AUTOSAR XML (schema 3.1.2)
package /Components/SWC_StopStrtEm
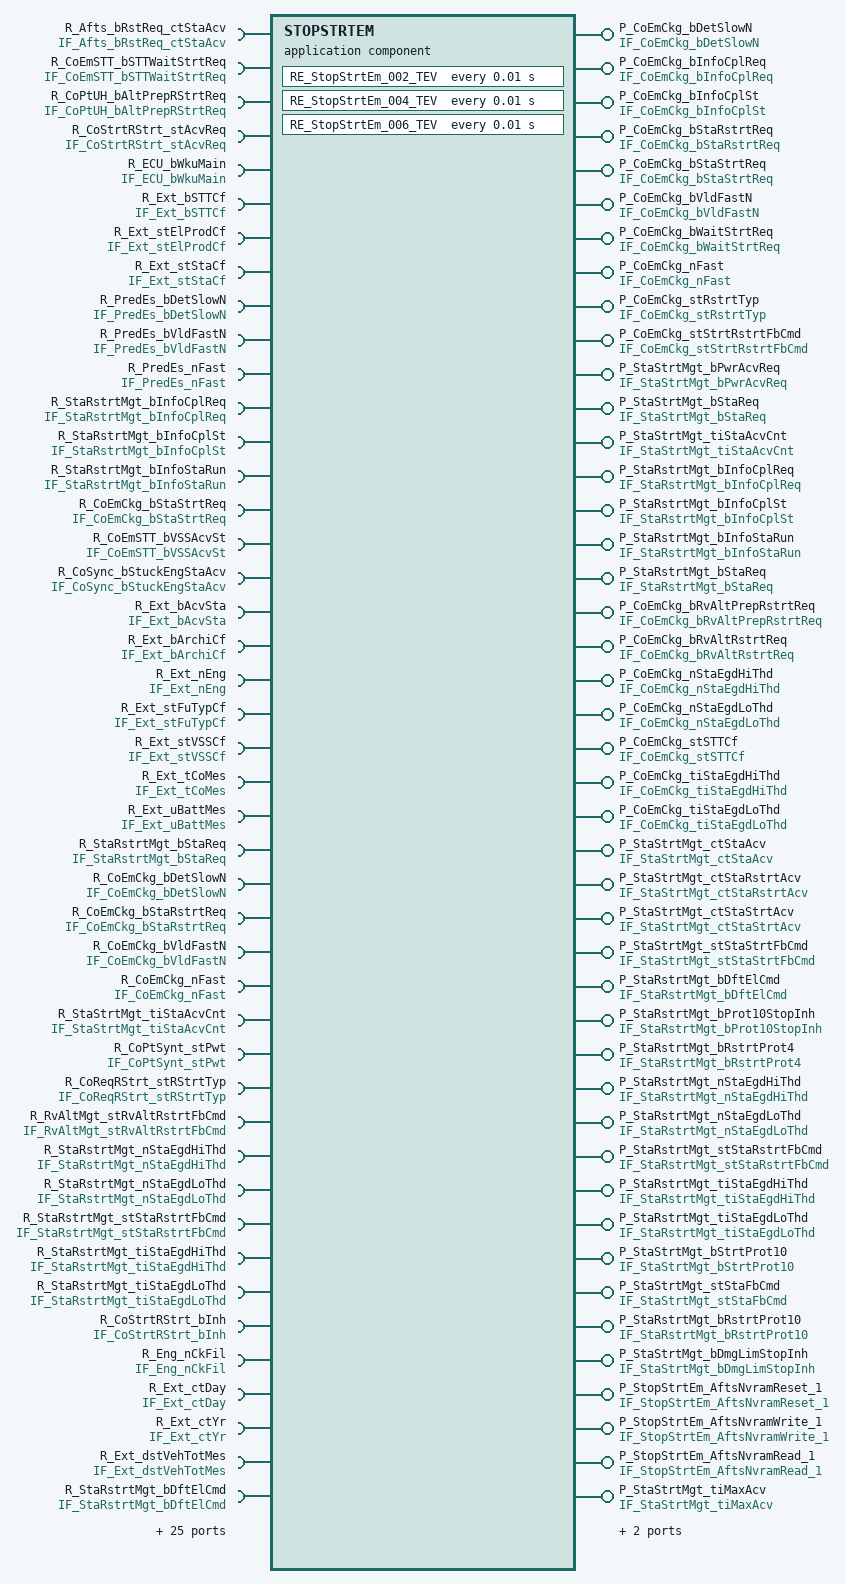
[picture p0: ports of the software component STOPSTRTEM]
  application software component type STOPSTRTEM
    57 x require port:
      R_Afts_bRstReq_ctStaAcv: unqueued-receiver-com-spec{data-element=Afts_bRstReq_ctStaAcv, init-value=Afts_bRstReq_ctStaAcv_in, resync-time=0}, required-interface=IF_Afts_bRstReq_ctStaAcv
      R_CoEmSTT_bSTTWaitStrtReq: unqueued-receiver-com-spec{data-element=CoEmSTT_bSTTWaitStrtReq, init-value=ConstantValue, resync-time=0}, required-interface=IF_CoEmSTT_bSTTWaitStrtReq
      R_CoPtUH_bAltPrepRStrtReq: unqueued-receiver-com-spec{data-element=CoPtUH_bAltPrepRStrtReq, init-value=ConstantValue1, resync-time=0}, required-interface=IF_CoPtUH_bAltPrepRStrtReq
      R_CoStrtRStrt_stAcvReq: unqueued-receiver-com-spec{data-element=CoStrtRStrt_stAcvReq, init-value=ConstantValue3, resync-time=0}, required-interface=IF_CoStrtRStrt_stAcvReq
      R_ECU_bWkuMain: unqueued-receiver-com-spec{data-element=ECU_bWkuMain, init-value=ConstantValue5, resync-time=0}, required-interface=IF_ECU_bWkuMain
      R_Ext_bSTTCf: unqueued-receiver-com-spec{data-element=Ext_bSTTCf, init-value=ConstantValue7, resync-time=0}, required-interface=IF_Ext_bSTTCf
      R_Ext_stElProdCf: unqueued-receiver-com-spec{data-element=Ext_stElProdCf, init-value=ConstantValue9, resync-time=0}, required-interface=IF_Ext_stElProdCf
      R_Ext_stStaCf: unqueued-receiver-com-spec{data-element=Ext_stStaCf, init-value=Ext_stStaCf_in, resync-time=0}, required-interface=IF_Ext_stStaCf
      R_PredEs_bDetSlowN: unqueued-receiver-com-spec{data-element=PredEs_bDetSlowN, init-value=PredEs_bDetSlowN_in, resync-time=0}, required-interface=IF_PredEs_bDetSlowN
      R_PredEs_bVldFastN: unqueued-receiver-com-spec{data-element=PredEs_bVldFastN, init-value=ConstantValue11, resync-time=0}, required-interface=IF_PredEs_bVldFastN
      R_PredEs_nFast: unqueued-receiver-com-spec{data-element=PredEs_nFast, init-value=ConstantValue13, resync-time=0}, required-interface=IF_PredEs_nFast
      R_StaRstrtMgt_bInfoCplReq: unqueued-receiver-com-spec{data-element=StaRstrtMgt_bInfoCplReq, init-value=StaRstrtMgt_bInfoCplReq_in, resync-time=0}, required-interface=IF_StaRstrtMgt_bInfoCplReq
      R_StaRstrtMgt_bInfoCplSt: unqueued-receiver-com-spec{data-element=StaRstrtMgt_bInfoCplSt, init-value=StaRstrtMgt_bInfoCplSt_in, resync-time=0}, required-interface=IF_StaRstrtMgt_bInfoCplSt
      R_StaRstrtMgt_bInfoStaRun: unqueued-receiver-com-spec{data-element=StaRstrtMgt_bInfoStaRun, init-value=StaRstrtMgt_bInfoStaRun_in, resync-time=0}, required-interface=IF_StaRstrtMgt_bInfoStaRun
      R_CoEmCkg_bStaStrtReq: unqueued-receiver-com-spec{data-element=CoEmCkg_bStaStrtReq, init-value=CoEmCkg_bStaStrtReq_in, resync-time=0}, required-interface=IF_CoEmCkg_bStaStrtReq
      R_CoEmSTT_bVSSAcvSt: unqueued-receiver-com-spec{data-element=CoEmSTT_bVSSAcvSt, init-value=ConstantValue15, resync-time=0}, required-interface=IF_CoEmSTT_bVSSAcvSt
      R_CoSync_bStuckEngStaAcv: unqueued-receiver-com-spec{data-element=CoSync_bStuckEngStaAcv, init-value=ConstantValue17, resync-time=0}, required-interface=IF_CoSync_bStuckEngStaAcv
      R_Ext_bAcvSta: unqueued-receiver-com-spec{data-element=Ext_bAcvSta, init-value=Ext_bAcvSta_in, resync-time=0}, required-interface=IF_Ext_bAcvSta
      R_Ext_bArchiCf: unqueued-receiver-com-spec{data-element=Ext_bArchiCf, init-value=ConstantValue19, resync-time=0}, required-interface=IF_Ext_bArchiCf
      R_Ext_nEng: unqueued-receiver-com-spec{data-element=Ext_nEng, init-value=ConstantValue21, resync-time=0}, required-interface=IF_Ext_nEng
      R_Ext_stFuTypCf: unqueued-receiver-com-spec{data-element=Ext_stFuTypCf, init-value=Ext_stFuTypCf_in, resync-time=0}, required-interface=IF_Ext_stFuTypCf
      R_Ext_stVSSCf: unqueued-receiver-com-spec{data-element=Ext_stVSSCf, init-value=ConstantValue23, resync-time=0}, required-interface=IF_Ext_stVSSCf
      R_Ext_tCoMes: unqueued-receiver-com-spec{data-element=Ext_tCoMes, init-value=ConstantValue25, resync-time=0}, required-interface=IF_Ext_tCoMes
      R_Ext_uBattMes: unqueued-receiver-com-spec{data-element=Ext_uBattMes, init-value=ConstantValue27, resync-time=0}, required-interface=IF_Ext_uBattMes
      R_StaRstrtMgt_bStaReq: unqueued-receiver-com-spec{data-element=StaRstrtMgt_bStaReq, init-value=StaRstrtMgt_bStaReq_in, resync-time=0}, required-interface=IF_StaRstrtMgt_bStaReq
      R_CoEmCkg_bDetSlowN: unqueued-receiver-com-spec{data-element=CoEmCkg_bDetSlowN, init-value=CoEmCkg_bDetSlowN_in, resync-time=0}, required-interface=IF_CoEmCkg_bDetSlowN
      R_CoEmCkg_bStaRstrtReq: unqueued-receiver-com-spec{data-element=CoEmCkg_bStaRstrtReq, init-value=CoEmCkg_bStaRstrtReq_in, resync-time=0}, required-interface=IF_CoEmCkg_bStaRstrtReq
      R_CoEmCkg_bVldFastN: unqueued-receiver-com-spec{data-element=CoEmCkg_bVldFastN, init-value=CoEmCkg_bVldFastN_in, resync-time=0}, required-interface=IF_CoEmCkg_bVldFastN
      R_CoEmCkg_nFast: unqueued-receiver-com-spec{data-element=CoEmCkg_nFast, init-value=CoEmCkg_nFast_in, resync-time=0}, required-interface=IF_CoEmCkg_nFast
      R_StaStrtMgt_tiStaAcvCnt: unqueued-receiver-com-spec{data-element=StaStrtMgt_tiStaAcvCnt, init-value=StaStrtMgt_tiStaAcvCnt_in, resync-time=0}, required-interface=IF_StaStrtMgt_tiStaAcvCnt
      R_CoPtSynt_stPwt: unqueued-receiver-com-spec{data-element=CoPtSynt_stPwt, init-value=ConstantValue29, resync-time=0}, required-interface=IF_CoPtSynt_stPwt
      R_CoReqRStrt_stRStrtTyp: unqueued-receiver-com-spec{data-element=CoReqRStrt_stRStrtTyp, init-value=ConstantValue31, resync-time=0}, required-interface=IF_CoReqRStrt_stRStrtTyp
      R_RvAltMgt_stRvAltRstrtFbCmd: unqueued-receiver-com-spec{data-element=RvAltMgt_stRvAltRstrtFbCmd, init-value=ConstantValue33, resync-time=0}, required-interface=IF_RvAltMgt_stRvAltRstrtFbCmd
      R_StaRstrtMgt_nStaEgdHiThd: unqueued-receiver-com-spec{data-element=StaRstrtMgt_nStaEgdHiThd, init-value=StaRstrtMgt_nStaEgdHiThd_in, resync-time=0}, required-interface=IF_StaRstrtMgt_nStaEgdHiThd
      R_StaRstrtMgt_nStaEgdLoThd: unqueued-receiver-com-spec{data-element=StaRstrtMgt_nStaEgdLoThd, init-value=StaRstrtMgt_nStaEgdLoThd_in, resync-time=0}, required-interface=IF_StaRstrtMgt_nStaEgdLoThd
      R_StaRstrtMgt_stStaRstrtFbCmd: unqueued-receiver-com-spec{data-element=StaRstrtMgt_stStaRstrtFbCmd, init-value=ConstantValue35, resync-time=0}, required-interface=IF_StaRstrtMgt_stStaRstrtFbCmd
      R_StaRstrtMgt_tiStaEgdHiThd: unqueued-receiver-com-spec{data-element=StaRstrtMgt_tiStaEgdHiThd, init-value=StaRstrtMgt_tiStaEgdHiThd_in, resync-time=0}, required-interface=IF_StaRstrtMgt_tiStaEgdHiThd
      R_StaRstrtMgt_tiStaEgdLoThd: unqueued-receiver-com-spec{data-element=StaRstrtMgt_tiStaEgdLoThd, init-value=StaRstrtMgt_tiStaEgdLoThd_in, resync-time=0}, required-interface=IF_StaRstrtMgt_tiStaEgdLoThd
      R_CoStrtRStrt_bInh: unqueued-receiver-com-spec{data-element=CoStrtRStrt_bInh, init-value=CoStrtRStrt_bInh_in, resync-time=0}, required-interface=IF_CoStrtRStrt_bInh
      R_Eng_nCkFil: unqueued-receiver-com-spec{data-element=Eng_nCkFil, init-value=ConstantValue37, resync-time=0}, required-interface=IF_Eng_nCkFil
      R_Ext_ctDay: unqueued-receiver-com-spec{data-element=Ext_ctDay, init-value=ConstantValue39, resync-time=0}, required-interface=IF_Ext_ctDay
      R_Ext_ctYr: unqueued-receiver-com-spec{data-element=Ext_ctYr, init-value=ConstantValue41, resync-time=0}, required-interface=IF_Ext_ctYr
      R_Ext_dstVehTotMes: unqueued-receiver-com-spec{data-element=Ext_dstVehTotMes, init-value=ConstantValue43, resync-time=0}, required-interface=IF_Ext_dstVehTotMes
      R_StaRstrtMgt_bDftElCmd: unqueued-receiver-com-spec{data-element=StaRstrtMgt_bDftElCmd, init-value=StaRstrtMgt_bDftElCmd_in, resync-time=0}, required-interface=IF_StaRstrtMgt_bDftElCmd
      R_StaRstrtMgt_bRstrtProt4: unqueued-receiver-com-spec{data-element=StaRstrtMgt_bRstrtProt4, init-value=StaRstrtMgt_bRstrtProt4_in, resync-time=0}, required-interface=IF_StaRstrtMgt_bRstrtProt4
      R_StaStrtMgt_ctStaAcv: unqueued-receiver-com-spec{data-element=StaStrtMgt_ctStaAcv, init-value=StaStrtMgt_ctStaAcv_in, resync-time=0}, required-interface=IF_StaStrtMgt_ctStaAcv
      R_StaStrtMgt_stStaFbCmd: unqueued-receiver-com-spec{data-element=StaStrtMgt_stStaFbCmd, init-value=StaStrtMgt_stStaFbCmd_in, resync-time=0}, required-interface=IF_StaStrtMgt_stStaFbCmd
      R_CoEmCkg_stSTTCf: unqueued-receiver-com-spec{data-element=CoEmCkg_stSTTCf, init-value=ConstantValue45, resync-time=0}, required-interface=IF_CoEmCkg_stSTTCf
      R_Ext_bStaCmdFctSt: unqueued-receiver-com-spec{data-element=Ext_bStaCmdFctSt, init-value=Ext_bStaCmdFctSt_in, resync-time=0}, required-interface=IF_Ext_bStaCmdFctSt
      R_FRM_bAcvStaStrtMgtDftValThd: required-interface=FunctionInhibition
      R_FRM_bAcvStaStrtMgtDiagElCmd: required-interface=FunctionInhibition
      R_FRM_bInhStaStrtMgtVoltFall: required-interface=FunctionInhibition
      R_FRM_bAcvStaRstrtMgtDftValThd: required-interface=FunctionInhibition
      R_FRM_bAcvStaRstrtMgtDiagElCmd: required-interface=FunctionInhibition
      R_FRM_bInhStaRstrtMgtVoltFall: required-interface=FunctionInhibition
      R_FRM_bInhStaStrtMgtDmgTiCnt: required-interface=FunctionInhibition
      R_FRM_bInhStaStrtMgtDmgVehDst: required-interface=FunctionInhibition
    40 x provide port:
      P_CoEmCkg_bDetSlowN: unqueued-sender-com-spec{data-element=CoEmCkg_bDetSlowN, can-invalidate=false, init-value=CoEmCkg_bDetSlowN_out}, provided-interface=IF_CoEmCkg_bDetSlowN
      P_CoEmCkg_bInfoCplReq: unqueued-sender-com-spec{data-element=CoEmCkg_bInfoCplReq, can-invalidate=false, init-value=CoEmCkg_bInfoCplReq_out}, provided-interface=IF_CoEmCkg_bInfoCplReq
      P_CoEmCkg_bInfoCplSt: unqueued-sender-com-spec{data-element=CoEmCkg_bInfoCplSt, can-invalidate=false, init-value=CoEmCkg_bInfoCplSt_out}, provided-interface=IF_CoEmCkg_bInfoCplSt
      P_CoEmCkg_bStaRstrtReq: unqueued-sender-com-spec{data-element=CoEmCkg_bStaRstrtReq, can-invalidate=false, init-value=CoEmCkg_bStaRstrtReq_out}, provided-interface=IF_CoEmCkg_bStaRstrtReq
      P_CoEmCkg_bStaStrtReq: unqueued-sender-com-spec{data-element=CoEmCkg_bStaStrtReq, can-invalidate=false, init-value=CoEmCkg_bStaStrtReq_out}, provided-interface=IF_CoEmCkg_bStaStrtReq
      P_CoEmCkg_bVldFastN: unqueued-sender-com-spec{data-element=CoEmCkg_bVldFastN, can-invalidate=false, init-value=CoEmCkg_bVldFastN_out}, provided-interface=IF_CoEmCkg_bVldFastN
      P_CoEmCkg_bWaitStrtReq: unqueued-sender-com-spec{data-element=CoEmCkg_bWaitStrtReq, can-invalidate=false, init-value=CoEmCkg_bWaitStrtReq_out}, provided-interface=IF_CoEmCkg_bWaitStrtReq
      P_CoEmCkg_nFast: unqueued-sender-com-spec{data-element=CoEmCkg_nFast, can-invalidate=false, init-value=CoEmCkg_nFast_out}, provided-interface=IF_CoEmCkg_nFast
      P_CoEmCkg_stRstrtTyp: unqueued-sender-com-spec{data-element=CoEmCkg_stRstrtTyp, can-invalidate=false, init-value=ConstantValue47}, provided-interface=IF_CoEmCkg_stRstrtTyp
      P_CoEmCkg_stStrtRstrtFbCmd: unqueued-sender-com-spec{data-element=CoEmCkg_stStrtRstrtFbCmd, can-invalidate=false, init-value=ConstantValue49}, provided-interface=IF_CoEmCkg_stStrtRstrtFbCmd
      P_StaStrtMgt_bPwrAcvReq: unqueued-sender-com-spec{data-element=StaStrtMgt_bPwrAcvReq, can-invalidate=false, init-value=StaStrtMgt_bPwrAcvReq_out}, provided-interface=IF_StaStrtMgt_bPwrAcvReq
      P_StaStrtMgt_bStaReq: unqueued-sender-com-spec{data-element=StaStrtMgt_bStaReq, can-invalidate=false, init-value=ConstantValue51}, provided-interface=IF_StaStrtMgt_bStaReq
      P_StaStrtMgt_tiStaAcvCnt: unqueued-sender-com-spec{data-element=StaStrtMgt_tiStaAcvCnt, can-invalidate=false, init-value=StaStrtMgt_tiStaAcvCnt_out}, provided-interface=IF_StaStrtMgt_tiStaAcvCnt
      P_StaRstrtMgt_bInfoCplReq: unqueued-sender-com-spec{data-element=StaRstrtMgt_bInfoCplReq, can-invalidate=false, init-value=StaRstrtMgt_bInfoCplReq_out}, provided-interface=IF_StaRstrtMgt_bInfoCplReq
      P_StaRstrtMgt_bInfoCplSt: unqueued-sender-com-spec{data-element=StaRstrtMgt_bInfoCplSt, can-invalidate=false, init-value=StaRstrtMgt_bInfoCplSt_out}, provided-interface=IF_StaRstrtMgt_bInfoCplSt
      P_StaRstrtMgt_bInfoStaRun: unqueued-sender-com-spec{data-element=StaRstrtMgt_bInfoStaRun, can-invalidate=false, init-value=StaRstrtMgt_bInfoStaRun_out}, provided-interface=IF_StaRstrtMgt_bInfoStaRun
      P_StaRstrtMgt_bStaReq: unqueued-sender-com-spec{data-element=StaRstrtMgt_bStaReq, can-invalidate=false, init-value=StaRstrtMgt_bStaReq_out}, provided-interface=IF_StaRstrtMgt_bStaReq
      P_CoEmCkg_bRvAltPrepRstrtReq: unqueued-sender-com-spec{data-element=CoEmCkg_bRvAltPrepRstrtReq, can-invalidate=false, init-value=CoEmCkg_bRvAltPrepRstrtReq_out}, provided-interface=IF_CoEmCkg_bRvAltPrepRstrtReq
      P_CoEmCkg_bRvAltRstrtReq: unqueued-sender-com-spec{data-element=CoEmCkg_bRvAltRstrtReq, can-invalidate=false, init-value=CoEmCkg_bRvAltRstrtReq_out}, provided-interface=IF_CoEmCkg_bRvAltRstrtReq
      P_CoEmCkg_nStaEgdHiThd: unqueued-sender-com-spec{data-element=CoEmCkg_nStaEgdHiThd, can-invalidate=false, init-value=CoEmCkg_nStaEgdHiThd_out}, provided-interface=IF_CoEmCkg_nStaEgdHiThd
      P_CoEmCkg_nStaEgdLoThd: unqueued-sender-com-spec{data-element=CoEmCkg_nStaEgdLoThd, can-invalidate=false, init-value=CoEmCkg_nStaEgdLoThd_out}, provided-interface=IF_CoEmCkg_nStaEgdLoThd
      P_CoEmCkg_stSTTCf: unqueued-sender-com-spec{data-element=CoEmCkg_stSTTCf, can-invalidate=false, init-value=ConstantValue53}, provided-interface=IF_CoEmCkg_stSTTCf
      P_CoEmCkg_tiStaEgdHiThd: unqueued-sender-com-spec{data-element=CoEmCkg_tiStaEgdHiThd, can-invalidate=false, init-value=CoEmCkg_tiStaEgdHiThd_out}, provided-interface=IF_CoEmCkg_tiStaEgdHiThd
      P_CoEmCkg_tiStaEgdLoThd: unqueued-sender-com-spec{data-element=CoEmCkg_tiStaEgdLoThd, can-invalidate=false, init-value=CoEmCkg_tiStaEgdLoThd_out}, provided-interface=IF_CoEmCkg_tiStaEgdLoThd
      P_StaStrtMgt_ctStaAcv: unqueued-sender-com-spec{data-element=StaStrtMgt_ctStaAcv, can-invalidate=false, init-value=StaStrtMgt_ctStaAcv_out}, provided-interface=IF_StaStrtMgt_ctStaAcv
      P_StaStrtMgt_ctStaRstrtAcv: unqueued-sender-com-spec{data-element=StaStrtMgt_ctStaRstrtAcv, can-invalidate=false, init-value=StaStrtMgt_ctStaRstrtAcv_out}, provided-interface=IF_StaStrtMgt_ctStaRstrtAcv
      P_StaStrtMgt_ctStaStrtAcv: unqueued-sender-com-spec{data-element=StaStrtMgt_ctStaStrtAcv, can-invalidate=false, init-value=StaStrtMgt_ctStaStrtAcv_out}, provided-interface=IF_StaStrtMgt_ctStaStrtAcv
      P_StaStrtMgt_stStaStrtFbCmd: unqueued-sender-com-spec{data-element=StaStrtMgt_stStaStrtFbCmd, can-invalidate=false, init-value=StaStrtMgt_stStaStrtFbCmd_out}, provided-interface=IF_StaStrtMgt_stStaStrtFbCmd
      P_StaRstrtMgt_bDftElCmd: unqueued-sender-com-spec{data-element=StaRstrtMgt_bDftElCmd, can-invalidate=false, init-value=StaRstrtMgt_bDftElCmd_out}, provided-interface=IF_StaRstrtMgt_bDftElCmd
      P_StaRstrtMgt_bProt10StopInh: unqueued-sender-com-spec{data-element=StaRstrtMgt_bProt10StopInh, can-invalidate=false, init-value=ConstantValue55}, provided-interface=IF_StaRstrtMgt_bProt10StopInh
      P_StaRstrtMgt_bRstrtProt4: unqueued-sender-com-spec{data-element=StaRstrtMgt_bRstrtProt4, can-invalidate=false, init-value=StaRstrtMgt_bRstrtProt4_out}, provided-interface=IF_StaRstrtMgt_bRstrtProt4
      P_StaRstrtMgt_nStaEgdHiThd: unqueued-sender-com-spec{data-element=StaRstrtMgt_nStaEgdHiThd, can-invalidate=false, init-value=StaRstrtMgt_nStaEgdHiThd_out}, provided-interface=IF_StaRstrtMgt_nStaEgdHiThd
      P_StaRstrtMgt_nStaEgdLoThd: unqueued-sender-com-spec{data-element=StaRstrtMgt_nStaEgdLoThd, can-invalidate=false, init-value=StaRstrtMgt_nStaEgdLoThd_out}, provided-interface=IF_StaRstrtMgt_nStaEgdLoThd
      P_StaRstrtMgt_stStaRstrtFbCmd: unqueued-sender-com-spec{data-element=StaRstrtMgt_stStaRstrtFbCmd, can-invalidate=false, init-value=ConstantValue57}, provided-interface=IF_StaRstrtMgt_stStaRstrtFbCmd
      P_StaRstrtMgt_tiStaEgdHiThd: unqueued-sender-com-spec{data-element=StaRstrtMgt_tiStaEgdHiThd, can-invalidate=false, init-value=StaRstrtMgt_tiStaEgdHiThd_out}, provided-interface=IF_StaRstrtMgt_tiStaEgdHiThd
      P_StaRstrtMgt_tiStaEgdLoThd: unqueued-sender-com-spec{data-element=StaRstrtMgt_tiStaEgdLoThd, can-invalidate=false, init-value=StaRstrtMgt_tiStaEgdLoThd_out}, provided-interface=IF_StaRstrtMgt_tiStaEgdLoThd
      P_StaStrtMgt_bStrtProt10: unqueued-sender-com-spec{data-element=StaStrtMgt_bStrtProt10, can-invalidate=false, init-value=StaStrtMgt_bStrtProt10_out}, provided-interface=IF_StaStrtMgt_bStrtProt10
      P_StaStrtMgt_stStaFbCmd: unqueued-sender-com-spec{data-element=StaStrtMgt_stStaFbCmd, can-invalidate=false, init-value=StaStrtMgt_stStaFbCmd_out}, provided-interface=IF_StaStrtMgt_stStaFbCmd
      P_StaRstrtMgt_bRstrtProt10: unqueued-sender-com-spec{data-element=StaRstrtMgt_bRstrtProt10, can-invalidate=false, init-value=StaRstrtMgt_bRstrtProt10_out}, provided-interface=IF_StaRstrtMgt_bRstrtProt10
      P_StaStrtMgt_bDmgLimStopInh: unqueued-sender-com-spec{data-element=StaStrtMgt_bDmgLimStopInh, can-invalidate=false, init-value=ConstantValue59}, provided-interface=IF_StaStrtMgt_bDmgLimStopInh
    8 x require port:
      R_StaStrtMgt_StaCmd: required-interface=DiagnosticMonitor
      R_StaStrtMgt_StaElCmd: required-interface=DiagnosticMonitor
      R_StaStrtMgt_StuckMec: required-interface=DiagnosticMonitor
      R_StaStrtMgt_StaAcvThd1: required-interface=DiagnosticMonitor
      R_StaStrtMgt_StaAcvThd2: required-interface=DiagnosticMonitor
      R_StaStrtMgt_StaCmdInfo: required-interface=DiagnosticMonitor
      R_UCE_stWkuMainRelSt: required-interface=IF_UCE_stWkuMainRelSt
      R_EcuM_CurrentMode: required-interface=EcuM_CurrentMode
    provide port P_StopStrtEm_AftsNvramReset_1: server-com-spec{operation=op_StopStrtEm_AftsNvramReset_1, queue-length=1}, provided-interface=IF_StopStrtEm_AftsNvramReset_1
    provide port P_StopStrtEm_AftsNvramWrite_1: server-com-spec{operation=op_StopStrtEm_AftsNvramWrite_1, queue-length=1}, provided-interface=IF_StopStrtEm_AftsNvramWrite_1
    provide port P_StopStrtEm_AftsNvramRead_1: server-com-spec{operation=op_StopStrtEm_AftsNvramRead_1, queue-length=1}, provided-interface=IF_StopStrtEm_AftsNvramRead_1
    require port R_Ext_ctSec: unqueued-receiver-com-spec{data-element=Ext_ctSec, init-value=ConstantValue61, resync-time=0}, required-interface=IF_Ext_ctSec
    provide port P_StaStrtMgt_tiMaxAcv: unqueued-sender-com-spec{data-element=StaStrtMgt_tiMaxAcv, can-invalidate=false, init-value=StaStrtMgt_tiMaxAcv_Cst}, provided-interface=IF_StaStrtMgt_tiMaxAcv
    require port R_StaStrtMgt_tiMaxAcv: unqueued-receiver-com-spec{data-element=StaStrtMgt_tiMaxAcv, init-value=StaStrtMgt_tiMaxAcv_Cst, resync-time=0}, required-interface=IF_StaStrtMgt_tiMaxAcv
    provide port P_CoEmCkg_bReqAltBoostFil: unqueued-sender-com-spec{data-element=CoEmCkg_bReqAltBoostFil, can-invalidate=false, init-value=CoEmCkg_bReqAltBoostFil_Cst}, provided-interface=IF_CoEmCkg_bReqAltBoostFil
    provide port P_CoEmCkg_stReqAltBoost: unqueued-sender-com-spec{data-element=CoEmCkg_stReqAltBoost, can-invalidate=false, init-value=CoEmCkg_stReqAltBoost_Cst}, provided-interface=IF_CoEmCkg_stReqAltBoost
    require port R_CoEmSTT_bAuthBoost: unqueued-receiver-com-spec{data-element=CoEmSTT_bAuthBoost, init-value=CoEmSTT_bAuthBoost_Cst, resync-time=0}, required-interface=IF_CoEmSTT_bAuthBoost
    require port R_TqLimUH_bAcvUnBlsEng: unqueued-receiver-com-spec{data-element=TqLimUH_bAcvUnBlsEng, init-value=ConstantValue63, resync-time=0}, required-interface=IF_TqLimUH_bAcvUnBlsEng
  95 x constant specification:
    Afts_bRstReq_ctStaAcv_in
      value:
        boolean literal Afts_bRstReq_ctStaAcv_in: type=DT_Afts_bRstReq_ctStaAcv, value=false
    CoEmCkg_bDetSlowN_in
      value:
        boolean literal CoEmCkg_bDetSlowN_in: type=DT_CoEmCkg_bDetSlowN, value=false
    CoEmCkg_bDetSlowN_out
      value:
        boolean literal CoEmCkg_bDetSlowN_out: type=DT_CoEmCkg_bDetSlowN, value=false
    CoEmCkg_bInfoCplReq_out
      value:
        boolean literal CoEmCkg_bInfoCplReq_out: type=DT_CoEmCkg_bInfoCplReq, value=false
    CoEmCkg_bInfoCplSt_out
      value:
        boolean literal CoEmCkg_bInfoCplSt_out: type=DT_CoEmCkg_bInfoCplSt, value=false
    CoEmCkg_bReqAltBoostFil_Cst
      value:
        boolean literal CoEmCkg_bReqAltBoostFil_Cst: type=DT_CoEmCkg_bReqAltBoostFil, value=false
    CoEmCkg_bRvAltPrepRstrtReq_out
      value:
        boolean literal CoEmCkg_bRvAltPrepRstrtReq_out: type=DT_CoEmCkg_bRvAltPrepRstrtReq, value=false
    CoEmCkg_bRvAltRstrtReq_out
      value:
        boolean literal CoEmCkg_bRvAltRstrtReq_out: type=DT_CoEmCkg_bRvAltRstrtReq, value=false
    CoEmCkg_bStaRstrtReq_in
      value:
        boolean literal CoEmCkg_bStaRstrtReq_in: type=DT_CoEmCkg_bStaRstrtReq, value=false
    CoEmCkg_bStaRstrtReq_out
      value:
        boolean literal CoEmCkg_bStaRstrtReq_out: type=DT_CoEmCkg_bStaRstrtReq, value=false
    CoEmCkg_bStaStrtReq_in
      value:
        boolean literal CoEmCkg_bStaStrtReq_in: type=DT_CoEmCkg_bStaStrtReq, value=false
    CoEmCkg_bStaStrtReq_out
      value:
        boolean literal CoEmCkg_bStaStrtReq_out: type=DT_CoEmCkg_bStaStrtReq, value=false
    CoEmCkg_bVldFastN_in
      value:
        boolean literal CoEmCkg_bVldFastN_in: type=DT_CoEmCkg_bVldFastN, value=false
    CoEmCkg_bVldFastN_out
      value:
        boolean literal CoEmCkg_bVldFastN_out: type=DT_CoEmCkg_bVldFastN, value=false
    CoEmCkg_bWaitStrtReq_out
      value:
        boolean literal CoEmCkg_bWaitStrtReq_out: type=DT_CoEmCkg_bWaitStrtReq, value=false
    CoEmCkg_nFast_in
      value:
        integer literal CoEmCkg_nFast_in: type=DT_CoEmCkg_nFast, value=0
    CoEmCkg_nFast_out
      value:
        integer literal CoEmCkg_nFast_out: type=DT_CoEmCkg_nFast, value=0
    CoEmCkg_nStaEgdHiThd_out
      value:
        integer literal CoEmCkg_nStaEgdHiThd_out: type=DT_CoEmCkg_nStaEgdHiThd, value=0
    CoEmCkg_nStaEgdLoThd_out
      value:
        integer literal CoEmCkg_nStaEgdLoThd_out: type=DT_CoEmCkg_nStaEgdLoThd, value=0
    CoEmCkg_stReqAltBoost_Cst
      value:
        integer literal CoEmCkg_stReqAltBoost_Cst: type=DT_CoEmCkg_stReqAltBoost, value=0
    CoEmCkg_tiStaEgdHiThd_out
      value:
        integer literal CoEmCkg_tiStaEgdHiThd_out: type=DT_CoEmCkg_tiStaEgdHiThd, value=60
    CoEmCkg_tiStaEgdLoThd_out
      value:
        integer literal CoEmCkg_tiStaEgdLoThd_out: type=DT_CoEmCkg_tiStaEgdLoThd, value=30
    CoEmSTT_bAuthBoost_Cst
      value:
        boolean literal CoEmSTT_bAuthBoost_Cst: type=DT_CoEmSTT_bAuthBoost, value=false
    ConstantValue
      value:
        boolean literal ConstantValue: type=DT_CoEmSTT_bSTTWaitStrtReq, value=false
    ConstantValue1
      value:
        boolean literal ConstantValue1: type=DT_CoPtUH_bAltPrepRStrtReq, value=false
    ConstantValue11
      value:
        boolean literal ConstantValue11: type=DT_PredEs_bVldFastN, value=false
    ConstantValue13
      value:
        integer literal ConstantValue13: type=DT_PredEs_nFast, value=0
    ConstantValue15
      value:
        boolean literal ConstantValue15: type=DT_CoEmSTT_bVSSAcvSt, value=false
    ConstantValue17
      value:
        boolean literal ConstantValue17: type=DT_CoSync_bStuckEngStaAcv, value=false
    ConstantValue19
      value:
        boolean literal ConstantValue19: type=DT_Ext_bArchiCf, value=false
    ConstantValue21
      value:
        integer literal ConstantValue21: type=DT_Ext_nEng, value=0
    ConstantValue23
      value:
        integer literal ConstantValue23: type=DT_Ext_stVSSCf, value=0
    ConstantValue25
      value:
        integer literal ConstantValue25: type=DT_Ext_tCoMes, value=20
    ConstantValue27
      value:
        integer literal ConstantValue27: type=DT_Ext_uBattMes, value=1200
    ConstantValue29
      value:
        integer literal ConstantValue29: type=DT_CoPtSynt_stPwt, value=1
    ConstantValue3
      value:
        integer literal ConstantValue3: type=DT_CoStrtRStrt_stAcvReq, value=0
    ConstantValue31
      value:
        integer literal ConstantValue31: type=DT_CoReqRStrt_stRStrtTyp, value=0
    ConstantValue33
      value:
        integer literal ConstantValue33: type=DT_RvAltMgt_stRvAltRstrtFbCmd, value=0
    ConstantValue35
      value:
        integer literal ConstantValue35: type=DT_StaRstrtMgt_stStaRstrtFbCmd, value=0
    ConstantValue37
      value:
        integer literal ConstantValue37: type=DT_Eng_nCkFil, value=0
    ConstantValue39
      value:
        integer literal ConstantValue39: type=DT_Ext_ctDay, value=0
    ConstantValue41
      value:
        integer literal ConstantValue41: type=DT_Ext_ctYr, value=0
    ConstantValue43
      value:
        integer literal ConstantValue43: type=DT_Ext_dstVehTotMes, value=0
    ConstantValue45
      value:
        integer literal ConstantValue45: type=DT_CoEmCkg_stSTTCf, value=0
    ConstantValue47
      value:
        integer literal ConstantValue47: type=DT_CoEmCkg_stRstrtTyp, value=0
    ConstantValue49
      value:
        integer literal ConstantValue49: type=DT_CoEmCkg_stStrtRstrtFbCmd, value=0
    ConstantValue5
      value:
        boolean literal ConstantValue5: type=DT_ECU_bWkuMain, value=false
    ConstantValue51
      value:
        boolean literal ConstantValue51: type=DT_StaStrtMgt_bStaReq, value=false
    ConstantValue53
      value:
        integer literal ConstantValue53: type=DT_CoEmCkg_stSTTCf, value=0
    ConstantValue55
      value:
        boolean literal ConstantValue55: type=DT_StaRstrtMgt_bProt10StopInh, value=false
    ConstantValue57
      value:
        integer literal ConstantValue57: type=DT_StaRstrtMgt_stStaRstrtFbCmd, value=0
    ConstantValue59
      value:
        boolean literal ConstantValue59: type=DT_StaStrtMgt_bDmgLimStopInh, value=false
    ConstantValue61
      value:
        integer literal ConstantValue61: type=DT_Ext_ctSec, value=0
    ConstantValue63
      value:
        boolean literal ConstantValue63: type=DT_TqLimUH_bAcvUnBlsEng, value=false
    ConstantValue7
      value:
        boolean literal ConstantValue7: type=DT_Ext_bSTTCf, value=false
    ConstantValue9
      value:
        integer literal ConstantValue9: type=DT_Ext_stElProdCf, value=0
    CoStrtRStrt_bInh_in
      value:
        boolean literal CoStrtRStrt_bInh_in: type=DT_CoStrtRStrt_bInh, value=true
    Ext_bAcvSta_in
      value:
        boolean literal Ext_bAcvSta_in: type=DT_Ext_bAcvSta, value=false
    Ext_bStaCmdFctSt_in
      value:
        boolean literal Ext_bStaCmdFctSt_in: type=DT_Ext_bStaCmdFctSt, value=false
    Ext_stFuTypCf_in
      value:
        integer literal Ext_stFuTypCf_in: type=DT_Ext_stFuTypCf, value=0
    Ext_stStaCf_in
      value:
        integer literal Ext_stStaCf_in: type=DT_Ext_stStaCf, value=1
    PredEs_bDetSlowN_in
      value:
        boolean literal PredEs_bDetSlowN_in: type=DT_PredEs_bDetSlowN, value=false
    StaRstrtMgt_bDftElCmd_in
      value:
        boolean literal StaRstrtMgt_bDftElCmd_in: type=DT_StaRstrtMgt_bDftElCmd, value=false
    StaRstrtMgt_bDftElCmd_out
      value:
        boolean literal StaRstrtMgt_bDftElCmd_out: type=DT_StaRstrtMgt_bDftElCmd, value=false
    StaRstrtMgt_bInfoCplReq_in
      value:
        boolean literal StaRstrtMgt_bInfoCplReq_in: type=DT_StaRstrtMgt_bInfoCplReq, value=false
    StaRstrtMgt_bInfoCplReq_out
      value:
        boolean literal StaRstrtMgt_bInfoCplReq_out: type=DT_StaRstrtMgt_bInfoCplReq, value=false
    StaRstrtMgt_bInfoCplSt_in
      value:
        boolean literal StaRstrtMgt_bInfoCplSt_in: type=DT_StaRstrtMgt_bInfoCplSt, value=false
    StaRstrtMgt_bInfoCplSt_out
      value:
        boolean literal StaRstrtMgt_bInfoCplSt_out: type=DT_StaRstrtMgt_bInfoCplSt, value=false
    StaRstrtMgt_bInfoStaRun_in
      value:
        boolean literal StaRstrtMgt_bInfoStaRun_in: type=DT_StaRstrtMgt_bInfoStaRun, value=false
    StaRstrtMgt_bInfoStaRun_out
      value:
        boolean literal StaRstrtMgt_bInfoStaRun_out: type=DT_StaRstrtMgt_bInfoStaRun, value=false
    StaRstrtMgt_bRstrtProt10_out
      value:
        boolean literal StaRstrtMgt_bRstrtProt10_out: type=DT_StaRstrtMgt_bRstrtProt10, value=false
    StaRstrtMgt_bRstrtProt4_in
      value:
        boolean literal StaRstrtMgt_bRstrtProt4_in: type=DT_StaRstrtMgt_bRstrtProt4, value=false
    StaRstrtMgt_bRstrtProt4_out
      value:
        boolean literal StaRstrtMgt_bRstrtProt4_out: type=DT_StaRstrtMgt_bRstrtProt4, value=false
    StaRstrtMgt_bStaReq_in
      value:
        boolean literal StaRstrtMgt_bStaReq_in: type=DT_StaRstrtMgt_bStaReq, value=false
    StaRstrtMgt_bStaReq_out
      value:
        boolean literal StaRstrtMgt_bStaReq_out: type=DT_StaRstrtMgt_bStaReq, value=false
    StaRstrtMgt_nStaEgdHiThd_in
      value:
        integer literal StaRstrtMgt_nStaEgdHiThd_in: type=DT_StaRstrtMgt_nStaEgdHiThd, value=0
    StaRstrtMgt_nStaEgdHiThd_out
      value:
        integer literal StaRstrtMgt_nStaEgdHiThd_out: type=DT_StaRstrtMgt_nStaEgdHiThd, value=0
    StaRstrtMgt_nStaEgdLoThd_in
      value:
        integer literal StaRstrtMgt_nStaEgdLoThd_in: type=DT_StaRstrtMgt_nStaEgdLoThd, value=0
    StaRstrtMgt_nStaEgdLoThd_out
      value:
        integer literal StaRstrtMgt_nStaEgdLoThd_out: type=DT_StaRstrtMgt_nStaEgdLoThd, value=0
    StaRstrtMgt_tiStaEgdHiThd_in
      value:
        integer literal StaRstrtMgt_tiStaEgdHiThd_in: type=DT_StaRstrtMgt_tiStaEgdHiThd, value=60
    StaRstrtMgt_tiStaEgdHiThd_out
      value:
        integer literal StaRstrtMgt_tiStaEgdHiThd_out: type=DT_StaRstrtMgt_tiStaEgdHiThd, value=60
    StaRstrtMgt_tiStaEgdLoThd_in
      value:
        integer literal StaRstrtMgt_tiStaEgdLoThd_in: type=DT_StaRstrtMgt_tiStaEgdLoThd, value=30
    StaRstrtMgt_tiStaEgdLoThd_out
      value:
        integer literal StaRstrtMgt_tiStaEgdLoThd_out: type=DT_StaRstrtMgt_tiStaEgdLoThd, value=30
    StaStrtMgt_bPwrAcvReq_out
      value:
        boolean literal StaStrtMgt_bPwrAcvReq_out: type=DT_StaStrtMgt_bPwrAcvReq, value=false
    StaStrtMgt_bStrtProt10_out
      value:
        boolean literal StaStrtMgt_bStrtProt10_out: type=DT_StaStrtMgt_bStrtProt10, value=false
    StaStrtMgt_ctStaAcv_in
      value:
        integer literal StaStrtMgt_ctStaAcv_in: type=DT_StaStrtMgt_ctStaAcv, value=0
    StaStrtMgt_ctStaAcv_out
      value:
        integer literal StaStrtMgt_ctStaAcv_out: type=DT_StaStrtMgt_ctStaAcv, value=0
    StaStrtMgt_ctStaRstrtAcv_out
      value:
        integer literal StaStrtMgt_ctStaRstrtAcv_out: type=DT_StaStrtMgt_ctStaRstrtAcv, value=0
    StaStrtMgt_ctStaStrtAcv_out
      value:
        integer literal StaStrtMgt_ctStaStrtAcv_out: type=DT_StaStrtMgt_ctStaStrtAcv, value=0
    StaStrtMgt_stStaFbCmd_in
      value:
        integer literal StaStrtMgt_stStaFbCmd_in: type=DT_StaStrtMgt_stStaFbCmd, value=0
    StaStrtMgt_stStaFbCmd_out
      value:
        integer literal StaStrtMgt_stStaFbCmd_out: type=DT_StaStrtMgt_stStaFbCmd, value=0
    StaStrtMgt_stStaStrtFbCmd_out
      value:
        integer literal StaStrtMgt_stStaStrtFbCmd_out: type=DT_StaStrtMgt_stStaStrtFbCmd, value=0
    StaStrtMgt_tiMaxAcv_Cst
      value:
        integer literal StaStrtMgt_tiMaxAcv_Cst: type=DT_StaStrtMgt_tiMaxAcv, value=0
    StaStrtMgt_tiStaAcvCnt_in
      value:
        integer literal StaStrtMgt_tiStaAcvCnt_in: type=DT_StaStrtMgt_tiStaAcvCnt, value=0
    StaStrtMgt_tiStaAcvCnt_out
      value:
        integer literal StaStrtMgt_tiStaAcvCnt_out: type=DT_StaStrtMgt_tiStaAcvCnt, value=0
  internal behavior IB_StopStrtEm: component=STOPSTRTEM
    timing event EV_StopStrtEm_002_TEV: mode-dependency=dependent-on-mode=R_UCE_stWkuMainRelSt.RCD_stWkuMainRelSt.Invalid, start-on-event=RE_StopStrtEm_002_TEV, period=0.01
    timing event EV_StopStrtEm_004_TEV: mode-dependency=dependent-on-mode=R_UCE_stWkuMainRelSt.RCD_stWkuMainRelSt.Invalid, start-on-event=RE_StopStrtEm_004_TEV, period=0.01
    mode switch event EV_StopStrtEm_001_MSE: start-on-event=RE_StopStrtEm_001_MSE, activation=ENTRY, mode=R_EcuM_CurrentMode.currentMode.RUN
    timing event EV_StopStrtEm_006_TEV: mode-dependency=dependent-on-mode=[R_UCE_stWkuMainRelSt.RCD_stWkuMainRelSt.PreMainWakeUp, R_UCE_stWkuMainRelSt.RCD_stWkuMainRelSt.PostMainWakeUp, R_UCE_stWkuMainRelSt.RCD_stWkuMainRelSt.Invalid], start-on-event=RE_StopStrtEm_006_TEV, period=0.01
    mode switch event EV_StopStrtEm_005_MSE: start-on-event=RE_StopStrtEm_005_MSE, activation=ENTRY, mode=R_EcuM_CurrentMode.currentMode.RUN
    operation invoked event EV_StopStrtEm_AftsNvramRead_1: start-on-event=RE_StopStrtEm_AftsNvramRead_1, operation=P_StopStrtEm_AftsNvramRead_1.op_StopStrtEm_AftsNvramRead_1
    operation invoked event EV_StopStrtEm_AftsNvramWrite_1: start-on-event=RE_StopStrtEm_AftsNvramWrite_1, operation=P_StopStrtEm_AftsNvramWrite_1.op_StopStrtEm_AftsNvramWrite_1
    operation invoked event EV_StopStrtEm_AftsNvramReset_1: start-on-event=RE_StopStrtEm_AftsNvramReset_1, operation=P_StopStrtEm_AftsNvramReset_1.op_StopStrtEm_AftsNvramReset_1
    mode switch event EV_StopStrtEm_003_MSE: start-on-event=RE_StopStrtEm_003_MSE, activation=ENTRY, mode=R_EcuM_CurrentMode.currentMode.RUN
    9 x runnable:
      RE_StopStrtEm_002_TEV
        22 x data receive point:
          dr_CoReqRStrt_stRStrtTyp: data-element=R_CoReqRStrt_stRStrtTyp.CoReqRStrt_stRStrtTyp
          dr_StaRstrtMgt_tiStaEgdLoThd: data-element=R_StaRstrtMgt_tiStaEgdLoThd.StaRstrtMgt_tiStaEgdLoThd
          dr_RvAltMgt_stRvAltRstrtFbCmd: data-element=R_RvAltMgt_stRvAltRstrtFbCmd.RvAltMgt_stRvAltRstrtFbCmd
          dr_StaRstrtMgt_tiStaEgdHiThd: data-element=R_StaRstrtMgt_tiStaEgdHiThd.StaRstrtMgt_tiStaEgdHiThd
          dr_StaRstrtMgt_bInfoCplReq: data-element=R_StaRstrtMgt_bInfoCplReq.StaRstrtMgt_bInfoCplReq
          dr_Ext_stStaCf: data-element=R_Ext_stStaCf.Ext_stStaCf
          dr_StaStrtMgt_stStaFbCmd: data-element=R_StaStrtMgt_stStaFbCmd.StaStrtMgt_stStaFbCmd
          dr_PredEs_bVldFastN: data-element=R_PredEs_bVldFastN.PredEs_bVldFastN
          dr_CoEmSTT_bSTTWaitStrtReq: data-element=R_CoEmSTT_bSTTWaitStrtReq.CoEmSTT_bSTTWaitStrtReq
          dr_CoPtSynt_stPwt: data-element=R_CoPtSynt_stPwt.CoPtSynt_stPwt
          dr_StaRstrtMgt_nStaEgdLoThd: data-element=R_StaRstrtMgt_nStaEgdLoThd.StaRstrtMgt_nStaEgdLoThd
          dr_StaRstrtMgt_nStaEgdHiThd: data-element=R_StaRstrtMgt_nStaEgdHiThd.StaRstrtMgt_nStaEgdHiThd
          dr_Ext_bSTTCf: data-element=R_Ext_bSTTCf.Ext_bSTTCf
          dr_CoPtUH_bAltPrepRStrtReq: data-element=R_CoPtUH_bAltPrepRStrtReq.CoPtUH_bAltPrepRStrtReq
          dr_PredEs_bDetSlowN: data-element=R_PredEs_bDetSlowN.PredEs_bDetSlowN
          dr_TqLimUH_bAcvUnBlsEng: data-element=R_TqLimUH_bAcvUnBlsEng.TqLimUH_bAcvUnBlsEng
          dr_CoStrtRStrt_stAcvReq: data-element=R_CoStrtRStrt_stAcvReq.CoStrtRStrt_stAcvReq
          dr_Ext_stElProdCf: data-element=R_Ext_stElProdCf.Ext_stElProdCf
          drp_CoEmSTT_bAuthBoost: data-element=R_CoEmSTT_bAuthBoost.CoEmSTT_bAuthBoost
          dr_StaRstrtMgt_bInfoCplSt: data-element=R_StaRstrtMgt_bInfoCplSt.StaRstrtMgt_bInfoCplSt
          dr_CoEmSTT_bVSSAcvSt: data-element=R_CoEmSTT_bVSSAcvSt.CoEmSTT_bVSSAcvSt
          dr_PredEs_nFast: data-element=R_PredEs_nFast.PredEs_nFast
        19 x data send point:
          ds_CoEmCkg_bRvAltRstrtReq: data-element=P_CoEmCkg_bRvAltRstrtReq.CoEmCkg_bRvAltRstrtReq
          ds_CoEmCkg_bVldFastN: data-element=P_CoEmCkg_bVldFastN.CoEmCkg_bVldFastN
          ds_CoEmCkg_bStaStrtReq: data-element=P_CoEmCkg_bStaStrtReq.CoEmCkg_bStaStrtReq
          ds_CoEmCkg_stSTTCf: data-element=P_CoEmCkg_stSTTCf.CoEmCkg_stSTTCf
          ds_CoEmCkg_nStaEgdHiThd: data-element=P_CoEmCkg_nStaEgdHiThd.CoEmCkg_nStaEgdHiThd
          ds_CoEmCkg_tiStaEgdHiThd: data-element=P_CoEmCkg_tiStaEgdHiThd.CoEmCkg_tiStaEgdHiThd
          ds_CoEmCkg_nFast: data-element=P_CoEmCkg_nFast.CoEmCkg_nFast
          ds_CoEmCkg_bStaRstrtReq: data-element=P_CoEmCkg_bStaRstrtReq.CoEmCkg_bStaRstrtReq
          ds_CoEmCkg_stStrtRstrtFbCmd: data-element=P_CoEmCkg_stStrtRstrtFbCmd.CoEmCkg_stStrtRstrtFbCmd
          ds_CoEmCkg_tiStaEgdLoThd: data-element=P_CoEmCkg_tiStaEgdLoThd.CoEmCkg_tiStaEgdLoThd
          ds_CoEmCkg_bInfoCplSt: data-element=P_CoEmCkg_bInfoCplSt.CoEmCkg_bInfoCplSt
          ds_CoEmCkg_bWaitStrtReq: data-element=P_CoEmCkg_bWaitStrtReq.CoEmCkg_bWaitStrtReq
          dsp_CoEmCkg_stReqAltBoost: data-element=P_CoEmCkg_stReqAltBoost.CoEmCkg_stReqAltBoost
          ds_CoEmCkg_bDetSlowN: data-element=P_CoEmCkg_bDetSlowN.CoEmCkg_bDetSlowN
          ds_CoEmCkg_bInfoCplReq: data-element=P_CoEmCkg_bInfoCplReq.CoEmCkg_bInfoCplReq
          ds_CoEmCkg_stRstrtTyp: data-element=P_CoEmCkg_stRstrtTyp.CoEmCkg_stRstrtTyp
          ds_CoEmCkg_nStaEgdLoThd: data-element=P_CoEmCkg_nStaEgdLoThd.CoEmCkg_nStaEgdLoThd
          dsp_CoEmCkg_bReqAltBoostFil: data-element=P_CoEmCkg_bReqAltBoostFil.CoEmCkg_bReqAltBoostFil
          ds_CoEmCkg_bRvAltPrepRstrtReq: data-element=P_CoEmCkg_bRvAltPrepRstrtReq.CoEmCkg_bRvAltPrepRstrtReq
      RE_StopStrtEm_AftsNvramWrite_1
      RE_StopStrtEm_AftsNvramRead_1
      RE_StopStrtEm_004_TEV
        30 x data receive point:
          dr_Afts_bRstReq_ctStaAcv: data-element=R_Afts_bRstReq_ctStaAcv.Afts_bRstReq_ctStaAcv
          dr_Ext_bSTTCf: data-element=R_Ext_bSTTCf.Ext_bSTTCf
          dr_Ext_bArchiCf: data-element=R_Ext_bArchiCf.Ext_bArchiCf
          dr_StaRstrtMgt_bInfoStaRun: data-element=R_StaRstrtMgt_bInfoStaRun.StaRstrtMgt_bInfoStaRun
          dr_Ext_nEng: data-element=R_Ext_nEng.Ext_nEng
          dr_CoEmCkg_stSTTCf: data-element=R_CoEmCkg_stSTTCf.CoEmCkg_stSTTCf
          dr_Ext_ctSec: data-element=R_Ext_ctSec.Ext_ctSec
          dr_Ext_bAcvSta: data-element=R_Ext_bAcvSta.Ext_bAcvSta
          dr_Ext_ctDay: data-element=R_Ext_ctDay.Ext_ctDay
          dr_Ext_bStaCmdFctSt: data-element=R_Ext_bStaCmdFctSt.Ext_bStaCmdFctSt
          dr_Ext_dstVehTotMes: data-element=R_Ext_dstVehTotMes.Ext_dstVehTotMes
          dr_CoEmCkg_nFast: data-element=R_CoEmCkg_nFast.CoEmCkg_nFast
          dr_StaRstrtMgt_bDftElCmd: data-element=R_StaRstrtMgt_bDftElCmd.StaRstrtMgt_bDftElCmd
          dr_Eng_nCkFil: data-element=R_Eng_nCkFil.Eng_nCkFil
          dr_CoEmCkg_bVldFastN: data-element=R_CoEmCkg_bVldFastN.CoEmCkg_bVldFastN
          dr_Ext_uBattMes: data-element=R_Ext_uBattMes.Ext_uBattMes
          dr_CoEmSTT_bVSSAcvSt: data-element=R_CoEmSTT_bVSSAcvSt.CoEmSTT_bVSSAcvSt
          dr_StaRstrtMgt_stStaRstrtFbCmd: data-element=R_StaRstrtMgt_stStaRstrtFbCmd.StaRstrtMgt_stStaRstrtFbCmd
          dr_Ext_stFuTypCf: data-element=R_Ext_stFuTypCf.Ext_stFuTypCf
          dr_Ext_stStaCf: data-element=R_Ext_stStaCf.Ext_stStaCf
          dr_Ext_tCoMes: data-element=R_Ext_tCoMes.Ext_tCoMes
          dr_CoPtSynt_stPwt: data-element=R_CoPtSynt_stPwt.CoPtSynt_stPwt
          dr_Ext_ctYr: data-element=R_Ext_ctYr.Ext_ctYr
          dr_CoStrtRStrt_bInh: data-element=R_CoStrtRStrt_bInh.CoStrtRStrt_bInh
          dr_Ext_stVSSCf: data-element=R_Ext_stVSSCf.Ext_stVSSCf
          dr_CoSync_bStuckEngStaAcv: data-element=R_CoSync_bStuckEngStaAcv.CoSync_bStuckEngStaAcv
          dr_StaRstrtMgt_bRstrtProt4: data-element=R_StaRstrtMgt_bRstrtProt4.StaRstrtMgt_bRstrtProt4
          dr_ECU_bWkuMain: data-element=R_ECU_bWkuMain.ECU_bWkuMain
          dr_StaRstrtMgt_bStaReq: data-element=R_StaRstrtMgt_bStaReq.StaRstrtMgt_bStaReq
          dr_CoEmCkg_bStaStrtReq: data-element=R_CoEmCkg_bStaStrtReq.CoEmCkg_bStaStrtReq
        11 x data send point:
          dsp_StaStrtMgt_tiMaxAcv: data-element=P_StaStrtMgt_tiMaxAcv.StaStrtMgt_tiMaxAcv
          ds_StaStrtMgt_ctStaStrtAcv: data-element=P_StaStrtMgt_ctStaStrtAcv.StaStrtMgt_ctStaStrtAcv
          ds_StaStrtMgt_stStaStrtFbCmd: data-element=P_StaStrtMgt_stStaStrtFbCmd.StaStrtMgt_stStaStrtFbCmd
          ds_StaStrtMgt_ctStaRstrtAcv: data-element=P_StaStrtMgt_ctStaRstrtAcv.StaStrtMgt_ctStaRstrtAcv
          ds_StaStrtMgt_bDmgLimStopInh: data-element=P_StaStrtMgt_bDmgLimStopInh.StaStrtMgt_bDmgLimStopInh
          ds_StaStrtMgt_tiStaAcvCnt: data-element=P_StaStrtMgt_tiStaAcvCnt.StaStrtMgt_tiStaAcvCnt
          ds_StaStrtMgt_ctStaAcv: data-element=P_StaStrtMgt_ctStaAcv.StaStrtMgt_ctStaAcv
          ds_StaStrtMgt_bPwrAcvReq: data-element=P_StaStrtMgt_bPwrAcvReq.StaStrtMgt_bPwrAcvReq
          ds_StaStrtMgt_bStrtProt10: data-element=P_StaStrtMgt_bStrtProt10.StaStrtMgt_bStrtProt10
          ds_StaStrtMgt_stStaFbCmd: data-element=P_StaStrtMgt_stStaFbCmd.StaStrtMgt_stStaFbCmd
          ds_StaStrtMgt_bStaReq: data-element=P_StaStrtMgt_bStaReq.StaStrtMgt_bStaReq
        11 x sync call:
          ssp_FRM_bInhStaStrtMgtDmgTiCnt: operation=R_FRM_bInhStaStrtMgtDmgTiCnt.GetFunctionPermission
          ssp_StaStrtMgt_StaCmdInfo: operation=R_StaStrtMgt_StaCmdInfo.SetEventStatus
          ssp_StaStrtMgt_StaAcvThd1: operation=R_StaStrtMgt_StaAcvThd1.SetEventStatus
          ssp_FRM_bAcvStaStrtMgtDftValThd: operation=R_FRM_bAcvStaStrtMgtDftValThd.GetFunctionPermission
          ssp_StaStrtMgt_StaCmd: operation=R_StaStrtMgt_StaCmd.SetEventStatus
          ssp_FRM_bInhStaStrtMgtVoltFall: operation=R_FRM_bInhStaStrtMgtVoltFall.GetFunctionPermission
          ssp_StaStrtMgt_StaAcvThd2: operation=R_StaStrtMgt_StaAcvThd2.SetEventStatus
          ssp_FRM_bInhStaStrtMgtDmgVehDst: operation=R_FRM_bInhStaStrtMgtDmgVehDst.GetFunctionPermission
          ssp_FRM_bAcvStaStrtMgtDiagElCmd: operation=R_FRM_bAcvStaStrtMgtDiagElCmd.GetFunctionPermission
          ssp_StaStrtMgt_StaElCmd: operation=R_StaStrtMgt_StaElCmd.SetEventStatus
          ssp_StaStrtMgt_StuckMec: operation=R_StaStrtMgt_StuckMec.SetEventStatus
      RE_StopStrtEm_AftsNvramReset_1
      RE_StopStrtEm_006_TEV
        18 x data receive point:
          dr_Ext_stVSSCf: data-element=R_Ext_stVSSCf.Ext_stVSSCf
          dr_ECU_bWkuMain: data-element=R_ECU_bWkuMain.ECU_bWkuMain
          dr_CoEmCkg_bDetSlowN: data-element=R_CoEmCkg_bDetSlowN.CoEmCkg_bDetSlowN
          dr_CoEmSTT_bVSSAcvSt: data-element=R_CoEmSTT_bVSSAcvSt.CoEmSTT_bVSSAcvSt
          drp_StaStrtMgt_tiMaxAcv: data-element=R_StaStrtMgt_tiMaxAcv.StaStrtMgt_tiMaxAcv
          dr_StaStrtMgt_tiStaAcvCnt: data-element=R_StaStrtMgt_tiStaAcvCnt.StaStrtMgt_tiStaAcvCnt
          dr_Ext_uBattMes: data-element=R_Ext_uBattMes.Ext_uBattMes
          dr_Ext_tCoMes: data-element=R_Ext_tCoMes.Ext_tCoMes
          dr_Eng_nCkFil: data-element=R_Eng_nCkFil.Eng_nCkFil
          dr_Ext_nEng: data-element=R_Ext_nEng.Ext_nEng
          dr_CoEmCkg_bVldFastN: data-element=R_CoEmCkg_bVldFastN.CoEmCkg_bVldFastN
          dr_Ext_bSTTCf: data-element=R_Ext_bSTTCf.Ext_bSTTCf
          dr_CoEmCkg_nFast: data-element=R_CoEmCkg_nFast.CoEmCkg_nFast
          dr_StaStrtMgt_ctStaAcv: data-element=R_StaStrtMgt_ctStaAcv.StaStrtMgt_ctStaAcv
          dr_Ext_bArchiCf: data-element=R_Ext_bArchiCf.Ext_bArchiCf
          dr_CoEmCkg_bStaRstrtReq: data-element=R_CoEmCkg_bStaRstrtReq.CoEmCkg_bStaRstrtReq
          dr_Ext_stFuTypCf: data-element=R_Ext_stFuTypCf.Ext_stFuTypCf
          dr_CoSync_bStuckEngStaAcv: data-element=R_CoSync_bStuckEngStaAcv.CoSync_bStuckEngStaAcv
        13 x data send point:
          ds_StaRstrtMgt_bDftElCmd: data-element=P_StaRstrtMgt_bDftElCmd.StaRstrtMgt_bDftElCmd
          ds_StaRstrtMgt_bStaReq: data-element=P_StaRstrtMgt_bStaReq.StaRstrtMgt_bStaReq
          ds_StaRstrtMgt_bInfoCplSt: data-element=P_StaRstrtMgt_bInfoCplSt.StaRstrtMgt_bInfoCplSt
          ds_StaRstrtMgt_bInfoCplReq: data-element=P_StaRstrtMgt_bInfoCplReq.StaRstrtMgt_bInfoCplReq
          ds_StaRstrtMgt_tiStaEgdLoThd: data-element=P_StaRstrtMgt_tiStaEgdLoThd.StaRstrtMgt_tiStaEgdLoThd
          ds_StaRstrtMgt_bInfoStaRun: data-element=P_StaRstrtMgt_bInfoStaRun.StaRstrtMgt_bInfoStaRun
          ds_StaRstrtMgt_tiStaEgdHiThd: data-element=P_StaRstrtMgt_tiStaEgdHiThd.StaRstrtMgt_tiStaEgdHiThd
          ds_StaRstrtMgt_stStaRstrtFbCmd: data-element=P_StaRstrtMgt_stStaRstrtFbCmd.StaRstrtMgt_stStaRstrtFbCmd
          ds_StaRstrtMgt_bProt10StopInh: data-element=P_StaRstrtMgt_bProt10StopInh.StaRstrtMgt_bProt10StopInh
          ds_StaRstrtMgt_nStaEgdHiThd: data-element=P_StaRstrtMgt_nStaEgdHiThd.StaRstrtMgt_nStaEgdHiThd
          ds_StaRstrtMgt_bRstrtProt10: data-element=P_StaRstrtMgt_bRstrtProt10.StaRstrtMgt_bRstrtProt10
          ds_StaRstrtMgt_nStaEgdLoThd: data-element=P_StaRstrtMgt_nStaEgdLoThd.StaRstrtMgt_nStaEgdLoThd
          ds_StaRstrtMgt_bRstrtProt4: data-element=P_StaRstrtMgt_bRstrtProt4.StaRstrtMgt_bRstrtProt4
        sync call ssp_FRM_bAcvStaRstrtMgtDftValThd: operation=R_FRM_bAcvStaRstrtMgtDftValThd.GetFunctionPermission
        sync call ssp_FRM_bAcvStaRstrtMgtDiagElCmd: operation=R_FRM_bAcvStaRstrtMgtDiagElCmd.GetFunctionPermission
        sync call ssp_FRM_bInhStaRstrtMgtVoltFall: operation=R_FRM_bInhStaRstrtMgtVoltFall.GetFunctionPermission
      RE_StopStrtEm_001_MSE
        19 x data send point:
          ds_CoEmCkg_nFast: data-element=P_CoEmCkg_nFast.CoEmCkg_nFast
          ds_CoEmCkg_stSTTCf: data-element=P_CoEmCkg_stSTTCf.CoEmCkg_stSTTCf
          ds_CoEmCkg_bDetSlowN: data-element=P_CoEmCkg_bDetSlowN.CoEmCkg_bDetSlowN
          dsp_CoEmCkg_stReqAltBoost: data-element=P_CoEmCkg_stReqAltBoost.CoEmCkg_stReqAltBoost
          ds_CoEmCkg_stStrtRstrtFbCmd: data-element=P_CoEmCkg_stStrtRstrtFbCmd.CoEmCkg_stStrtRstrtFbCmd
          ds_CoEmCkg_bInfoCplReq: data-element=P_CoEmCkg_bInfoCplReq.CoEmCkg_bInfoCplReq
          ds_CoEmCkg_bRvAltRstrtReq: data-element=P_CoEmCkg_bRvAltRstrtReq.CoEmCkg_bRvAltRstrtReq
          ds_CoEmCkg_bInfoCplSt: data-element=P_CoEmCkg_bInfoCplSt.CoEmCkg_bInfoCplSt
          ds_CoEmCkg_tiStaEgdHiThd: data-element=P_CoEmCkg_tiStaEgdHiThd.CoEmCkg_tiStaEgdHiThd
          ds_CoEmCkg_bVldFastN: data-element=P_CoEmCkg_bVldFastN.CoEmCkg_bVldFastN
          ds_CoEmCkg_bStaRstrtReq: data-element=P_CoEmCkg_bStaRstrtReq.CoEmCkg_bStaRstrtReq
          ds_CoEmCkg_nStaEgdLoThd: data-element=P_CoEmCkg_nStaEgdLoThd.CoEmCkg_nStaEgdLoThd
          ds_CoEmCkg_bStaStrtReq: data-element=P_CoEmCkg_bStaStrtReq.CoEmCkg_bStaStrtReq
          ds_CoEmCkg_bRvAltPrepRstrtReq: data-element=P_CoEmCkg_bRvAltPrepRstrtReq.CoEmCkg_bRvAltPrepRstrtReq
          dsp_CoEmCkg_bReqAltBoostFil: data-element=P_CoEmCkg_bReqAltBoostFil.CoEmCkg_bReqAltBoostFil
          ds_CoEmCkg_stRstrtTyp: data-element=P_CoEmCkg_stRstrtTyp.CoEmCkg_stRstrtTyp
          ds_CoEmCkg_bWaitStrtReq: data-element=P_CoEmCkg_bWaitStrtReq.CoEmCkg_bWaitStrtReq
          ds_CoEmCkg_nStaEgdHiThd: data-element=P_CoEmCkg_nStaEgdHiThd.CoEmCkg_nStaEgdHiThd
          ds_CoEmCkg_tiStaEgdLoThd: data-element=P_CoEmCkg_tiStaEgdLoThd.CoEmCkg_tiStaEgdLoThd
      RE_StopStrtEm_005_MSE
        13 x data send point:
          ds_StaRstrtMgt_bInfoCplSt: data-element=P_StaRstrtMgt_bInfoCplSt.StaRstrtMgt_bInfoCplSt
          ds_StaRstrtMgt_bInfoStaRun: data-element=P_StaRstrtMgt_bInfoStaRun.StaRstrtMgt_bInfoStaRun
          ds_StaRstrtMgt_tiStaEgdHiThd: data-element=P_StaRstrtMgt_tiStaEgdHiThd.StaRstrtMgt_tiStaEgdHiThd
          ds_StaRstrtMgt_bDftElCmd: data-element=P_StaRstrtMgt_bDftElCmd.StaRstrtMgt_bDftElCmd
          ds_StaRstrtMgt_bInfoCplReq: data-element=P_StaRstrtMgt_bInfoCplReq.StaRstrtMgt_bInfoCplReq
          ds_StaRstrtMgt_nStaEgdHiThd: data-element=P_StaRstrtMgt_nStaEgdHiThd.StaRstrtMgt_nStaEgdHiThd
          ds_StaRstrtMgt_nStaEgdLoThd: data-element=P_StaRstrtMgt_nStaEgdLoThd.StaRstrtMgt_nStaEgdLoThd
          ds_StaRstrtMgt_stStaRstrtFbCmd: data-element=P_StaRstrtMgt_stStaRstrtFbCmd.StaRstrtMgt_stStaRstrtFbCmd
          ds_StaRstrtMgt_bRstrtProt10: data-element=P_StaRstrtMgt_bRstrtProt10.StaRstrtMgt_bRstrtProt10
          ds_StaRstrtMgt_bProt10StopInh: data-element=P_StaRstrtMgt_bProt10StopInh.StaRstrtMgt_bProt10StopInh
          ds_StaRstrtMgt_bStaReq: data-element=P_StaRstrtMgt_bStaReq.StaRstrtMgt_bStaReq
          ds_StaRstrtMgt_bRstrtProt4: data-element=P_StaRstrtMgt_bRstrtProt4.StaRstrtMgt_bRstrtProt4
          ds_StaRstrtMgt_tiStaEgdLoThd: data-element=P_StaRstrtMgt_tiStaEgdLoThd.StaRstrtMgt_tiStaEgdLoThd
      RE_StopStrtEm_003_MSE
        11 x data send point:
          ds_StaStrtMgt_bStaReq: data-element=P_StaStrtMgt_bStaReq.StaStrtMgt_bStaReq
          ds_StaStrtMgt_stStaStrtFbCmd: data-element=P_StaStrtMgt_stStaStrtFbCmd.StaStrtMgt_stStaStrtFbCmd
          ds_StaStrtMgt_bDmgLimStopInh: data-element=P_StaStrtMgt_bDmgLimStopInh.StaStrtMgt_bDmgLimStopInh
          dsp_StaStrtMgt_tiMaxAcv: data-element=P_StaStrtMgt_tiMaxAcv.StaStrtMgt_tiMaxAcv
          ds_StaStrtMgt_ctStaStrtAcv: data-element=P_StaStrtMgt_ctStaStrtAcv.StaStrtMgt_ctStaStrtAcv
          ds_StaStrtMgt_stStaFbCmd: data-element=P_StaStrtMgt_stStaFbCmd.StaStrtMgt_stStaFbCmd
          ds_StaStrtMgt_bPwrAcvReq: data-element=P_StaStrtMgt_bPwrAcvReq.StaStrtMgt_bPwrAcvReq
          ds_StaStrtMgt_ctStaAcv: data-element=P_StaStrtMgt_ctStaAcv.StaStrtMgt_ctStaAcv
          ds_StaStrtMgt_ctStaRstrtAcv: data-element=P_StaStrtMgt_ctStaRstrtAcv.StaStrtMgt_ctStaRstrtAcv
          ds_StaStrtMgt_tiStaAcvCnt: data-element=P_StaStrtMgt_tiStaAcvCnt.StaStrtMgt_tiStaAcvCnt
          ds_StaStrtMgt_bStrtProt10: data-element=P_StaStrtMgt_bStrtProt10.StaStrtMgt_bStrtProt10
  swc implementation Imp_StopStrtEm: programming-language=C, behavior=IB_StopStrtEm
    code-descriptors:
      code CodeDescriptor: type=SRC
        18 x xfile:
          StopStrtEm_004_calibrations_h: url=StopStrtEm_004_calibrations.h
          StopStrtEm_nvm_h: url=StopStrtEm_nvm.h
          StopStrtEm_006_calibrations_c: url=StopStrtEm_006_calibrations.c
          StopStrtEm_002_TEV_fct_c: url=StopStrtEm_002_TEV_fct.c
          StopStrtEm_afts_c: url=StopStrtEm_afts.c
          StopStrtEm_004_TEV_fct_h: url=StopStrtEm_004_TEV_fct.h
          StopStrtEm_004_TEV_fct_c: url=StopStrtEm_004_TEV_fct.c
          StopStrtEm_MemMap_h: url=StopStrtEm_MemMap.h
          StopStrtEm_002_calibrations_h: url=StopStrtEm_002_calibrations.h
          StopStrtEm_006_TEV_fct_h: url=StopStrtEm_006_TEV_fct.h
          StopStrtEm_002_calibrations_c: url=StopStrtEm_002_calibrations.c
          StopStrtEm_006_calibrations_h: url=StopStrtEm_006_calibrations.h
          StopStrtEm_nvm_c: url=StopStrtEm_nvm.c
          StopStrtEm_002_TEV_fct_h: url=StopStrtEm_002_TEV_fct.h
          StopStrtEm_006_TEV_fct_c: url=StopStrtEm_006_TEV_fct.c
          StopStrtEm_004_calibrations_c: url=StopStrtEm_004_calibrations.c
          StopStrtEm_h: url=StopStrtEm.h
          StopStrtEm_c: url=StopStrtEm.c
